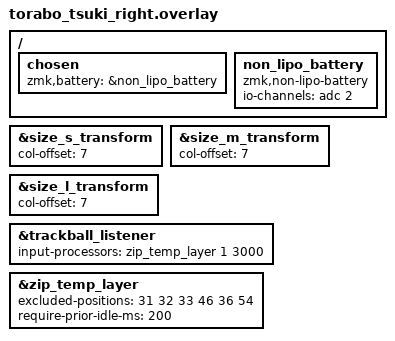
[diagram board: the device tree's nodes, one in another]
#include "torabo_tsuki.dtsi"
#include <input/processors.dtsi>
#include <dt-bindings/zmk/input_transform.h>

&size_s_transform {
    col-offset = <7>;
};

&size_m_transform {
    col-offset = <7>;
};

&size_l_transform {
    col-offset = <7>;
};

&trackball_listener {
    input-processors = <
        &zip_temp_layer 1 3000
    >;
};

&zip_temp_layer {
    excluded-positions = <
        31 // J
        32 // K
        33 // L
        46 // <
        36 // LEFT_SHIFT
        54 // LEFT_GUI
    >;

    require-prior-idle-ms = <200>;
};

/ {
    chosen {
        zmk,battery = &non_lipo_battery;
    };

    non_lipo_battery: non_lipo_battery {
        compatible = "zmk,non-lipo-battery";
        io-channels = <&adc 2>;  // 使用するADCチャンネル
    };
};
